# SF32LB52x register map
File version: 1.0
CPU: CM33 r0p1, little endian, MPU, FPU, 3 interrupt priority bits
Registers are 32-bit, read-write, reset 0x0 unless marked. A register's access mark holds for its fields unless they carry their own. Offsets are from the block's base; [hi:lo] are bit positions; {n}, {i} and the like mark numbered series.

## SPI1 — SPI
Base 0x50095000
Same registers: SPI2 0x50096000
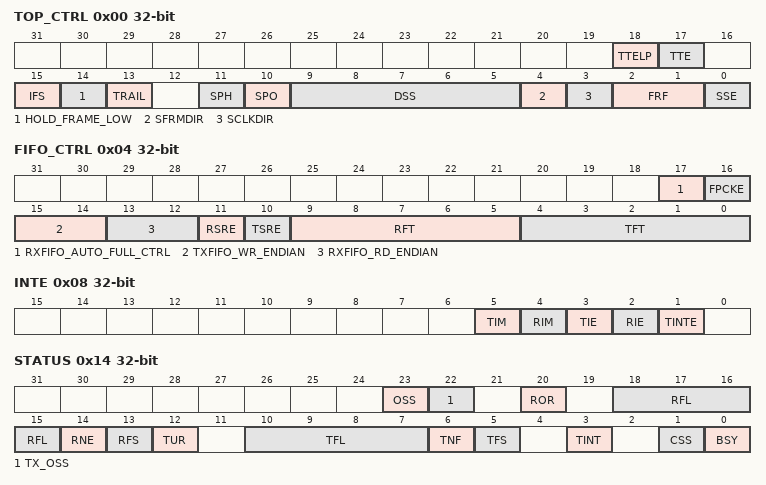
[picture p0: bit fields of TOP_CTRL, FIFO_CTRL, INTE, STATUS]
0x00 TOP_CTRL — Top Control Register
  [18] TTELP — SPI_DO Three-state Enable On Last Phase (can be set only when TI-SSP) 0: SPI_DO is three-stated 1/2 clock cycle after the beginning of the LSB 1: SPI_DO output signal is three-stated on the clock edge that ends the LSB
  [17] TTE — SPI_DO Three-State Enable 0: SPI_DO output signal is not three-stated 1: SPI_DO is three-stated when not transmitting data
  [15] IFS — Invert Frame Signal 0: SPI_CS polarity is as defined in protocol 1: SPI_CS will be inverted from normal-SPI_CS
  [14] HOLD_FRAME_LOW — Hold Frame Low Control 0:After this field is set to 1 and the SPI controller is operating in master mode,the output frame signal SPI_CS will be determined by control FSM. 1:After this field is set to 1 and the SPI controller is operating in master mode, the output frame signal SPI_CS will hold low.
  [13] TRAIL — Trailing Byte 0: Trailing bytes are handled by CPU 1: Trailing bytes are handled by DMA bursts
  [11] SPH — Motorola SPI SPI_CLK phase setting 0: SPI_CLK is inactive until one cycle after the start of a frame and active until 1/2 cycle before the end of a frame 1: SPI_CLK is inactive until 1/2 cycle after the start of a frame and active until one cycle before the end of a frame
  [10] SPO — Motorola SPI SPI_CLK Polarity Setting 0: The inactive or idle state of SPI_CLK is low 1: The inactive or idle state of SPI_CLK is high
  [9:5] DSS — SPI controller Work data size, register bits value 0~31 indicated data size 1~32 bits, usually use data size 8bits, 16bits, 24bits, 32bits
  [4] SFRMDIR — SPI_CS Direction 0: Master mode, SPI controller drives SPI_CS 1: Slave mode, SPI controller receives SPI_CS
  [3] SCLKDIR — SPI_CLK Direction 0: Master mode, SPI controller drives SPI_CLK 1: Slave mode, SPI controller receives SPI_CLK
  [2:1] FRF — Frame Format 0x0: Motorola* Serial Peripheral Interface (SPI) 0x1: Texas Instruments* Synchronous Serial Protocol (SSP) 0x2: National Semiconductor Microwire* 0x3: RSVD
  [0] SSE — SPI controller Enable 0: SPI controller is disabled 1: SPI controller is enabled
0x04 FIFO_CTRL — FIFO Control Register
  [17] RXFIFO_AUTO_FULL_CTRL — Rx FIFO Auto Full Control: After this field is set to 1 and the SPI controller is operating in master mode, the controller FSM returns to IDLE state and stops the SPI_CLK. When Rx FIFO is full, the controller FSM continues transferring data after the RxFIFO is not full. This field is used to avoid an RxFIFO overrun issue. 1: Enable Rx FIFO auto full control
  [16] FPCKE — FIFO Packing Enable 0: FIFO packing mode disabled 1: FIFO packing mode enabled
  [15:14] TXFIFO_WR_ENDIAN — apb_pwdata Write to TxFIFO Endian 0x0: txfifo_wdata[31:0] = apb_pwdata[31:0] 0x1: fifo_wdata[31:0] = {apb_pwdata[15:0], apb_pwdata[31:16]} 0x2: txfifo_wdata[31:0] = {apb_pwdata[7:0], apb_pwdata[15:8], apb_pwdata[23:16], apb_pwdata[31:24]} 0x3: txfifo_wdata[31:0] = {apb_pwdata[23:16], apb_pwdata[31:24], apb_pwdata[7:0], apb_pwdata[15:8]}
  [13:12] RXFIFO_RD_ENDIAN — apb_prdata Read from Rx FIFO Endian 0x0 = apb_prdata[31:0] = rxfifo_wdata[31:0] 0x1 = apb_prdata[31:0] = {rxfifo_wdata[15:0], rxfifo_wdata[31:16]} 0x2 = apb_prdata[31:0]= {rxfifo_wdata[7:0], rxfifo_wdata[15:8], rxfifo_wdata[23:16], rxfifo_wdata[31:24]} 0x3 = apb_prdata[31:0]= {rxfifo_wdata[23:16], rxfifo_wdata[31:24], rxfifo_wdata[7:0], rxfifo_wdata[15:8]}
  [11] RSRE — Receive Service Request Enable 0: RxFIFO DMA service request is disabled 1: RxFIFO DMA service request is enabled
  [10] TSRE — Transmit Service Request Enable 0: TxFIFO DMA service request is disabled 1: TxFIFO DMA service request is enabled
  [9:5] RFT — RXFIFO Trigger Threshold This field sets the threshold level at which RXFIFO asserts interrupt. The level should be set to the preferred threshold value minus 1.
  [4:0] TFT — TXFIFO Trigger Threshold This field sets the threshold level at which TXFIFO asserts interrupt. The level should be set to the preferred threshold value minus 1.
0x08 INTE — Interrupt Enable Register
  [5] TIM — Transmit FIFO Underrun Interrupt Mask 0 : TUR events generate an SPI interrupt 1 : TUR events do NOT generate an SPI interrupt
  [4] RIM — Receive FIFO Overrun Interrupt Mask 0: ROR events generate an SPI interrupt 1: ROR events do NOT generate an SPI interrupt
  [3] TIE — Transmit FIFO Interrupt Enable 0: TxFIFO threshold-level-reached interrupt is disabled 1: TxFIFO threshold-level-reached interrupt is enabled
  [2] RIE — Receive FIFO Interrupt Enable 0: RxFIFO threshold-level-reached interrupt is disabled 1: RxFIFO threshold-level-reached interrupt is enabled
  [1] TINTE — Receiver Time-out Interrupt Enable 0: Receiver time-out interrupt is disabled 1: Receiver time-out interrupt is enabled
0x0C TO — SPI Time Out Register
  [23:0] TIMEOUT — Timeout Value TIMEOUT value is the value (0 to 2^24-1) that defines the time-out interval. The time-out interval is given by the equation shown in the TIMEOUT Interval Equation.
0x10 DATA — SPI DATA Register
  [31:0] DATA — DATA This field is used for data to be written to the TXFIFO read from the RXFIFO.
0x14 STATUS
  [23] OSS — Odd Sample Status 0: RxFIFO entry has two samples 1: RxFIFO entry has one sample Note that this bit needs to be looked at only when FIFO Packing is enabled (FPCKE field in FIFO Control Register is set). Otherwise, this bit is zero. When SPI controller is in Packed mode and the CPU is used instead of DMA to read the RxFIFO, the CPU should make sure that [Receive FIFO Not Empty] = 1 AND this field = 0 before it attempts to read the RxFIFO.
  [22] TX_OSS — TX FIFO Odd Sample Status When SPI controller is in packed mode, the number of samples in the TX FIFO is: ([Transmit FIFO Level]*2 + this field), when [Transmit FIFO Not Full] = 1 32, when [Transmit FIFO Not Full] = 0. The TX FIFO cannot accept new data when [Transmit FIFO Not Full] = 1 and [Transmit FIFO Level] = 15 and this field = 1. (The TX FIFO has 31 samples). 0: TxFIFO entry has an even number of samples 1: TxFIFO entry has an odd number of samples Note that this bit needs to be read only when FIFO Packing is enabled ([FIFO Packing Enable] in the FIFO Control Register is set). Otherwise, this bit is zero.
  [20] ROR — Receive FIFO Overrun 0: RXFIFO has not experienced an overrun 1: Attempted data write to full RXFIFO, causes an interrupt request
  [18:15] RFL — Receive FIFO Level This field is the number of entries minus one in RXFIFO. When the value 0xF is read, the RXFIFO is either empty or full, and software should read the [Receive FIFO Not Empty] field.
  [14] RNE — Receive FIFO Not Empty 0: RXFIFO is empty 1: RXFIFO is not empty
  [13] RFS — Receive FIFO Service Request 0: RXFIFO level is at or below RFT threshold (RFT) or SPI controller is disabled 1: RXFIFO level exceeds RFT threshold (RFT), causes an interrupt request
  [12] TUR — Transmit FIFO Underrun 0: The TXFIFO has not experienced an underrun 1: A read from the TXFIFO was attempted when the TXFIFO was empty, causes an interrupt if it is enabled ([Transmit FIFO Underrun Interrupt Mask] in the INT EN Register is 0)
  [10:7] TFL — Transmit FIFO Level This field is the number of entries in TXFIFO.When the value 0x0 is read, the TXFIFO is either empty or full, and software should read the [Transmit FIFO Not Full] field.
  [6] TNF — Transmit FIFO Not Full 0: TXFIFO is full 1: TXFIFO is not full
  [5] TFS — Transmit FIFO Service Request 0: TX FIFO level exceeds the TFT threshold (TFT + 1) or SPI controller is disabled 1: TXFIFO level is at or below TFT threshold (TFT + 1), causes an interrupt request
  [3] TINT — Receiver Time-out Interrupt 0: No receiver time-out is pending 1: Receiver time-out pending, causes an interrupt request
  [1] CSS — Clock Synchronization Status 0: SPI controller is ready for slave clock operations 1: SPI controller is currently busy synchronizing slave mode signals
  [0] BSY — SPI controller Busy 0: SPI controller is idle or disabled 1: SPI controller is currently transmitting or receiving framed data
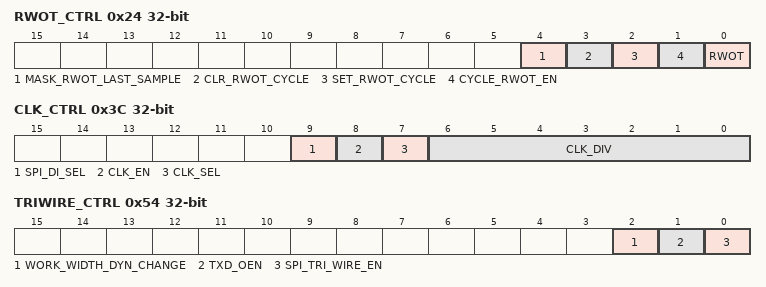
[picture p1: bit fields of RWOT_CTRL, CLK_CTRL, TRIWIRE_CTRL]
0x24 RWOT_CTRL — RWOT Control Register
  [4] MASK_RWOT_LAST_SAMPLE — Mask last_sample_flag in RWOT Mode 1: Mask 0: Unmask
  [3] CLR_RWOT_CYCLE — Clear Internal rwot_counter This field clears the rwot_counter to 0. This field is self cleared after SSE = 1. 1: Clear rwot_counter
  [2] SET_RWOT_CYCLE — Set RWOT Cycle This field is used to set the value of the RWOT_CCM register to the internal rwot_counter. This field is self-cleared after SSE = 1. 1: Set rwot_counter
  [1] CYCLE_RWOT_EN — Enable RWOT Cycle Counter Mode 1: Enable
  [0] RWOT — Receive Without Transmit 0: Transmit/receive mode 1: Receive without transmit mode
0x28 RWOT_CCM — RWOT Counter Cycles Match Register
  [31:0] RWOTCCM — It's just total SPI_CLK Cycles. The value of this register defines the total number of SPI_CLK cycles when SPI controller works in master and RWOT mode. When the rwot_counter matches this value, SPI controller returns to IDLE state and does not output SPI_CLK anymore.
0x2C RWOT_CVWRN — RWOT Counter Value Write for Red Request Register
  [31:0] RWOTCVWR — RWOTCVWR This register prevents the risk of instability on rwot_counter value reading, it's only valid after SPI controller has been enabled Write 0 = No effect Write 1 = Capture value of rwot_counter Read: Returns the captured value of rwot_counter
0x3C CLK_CTRL — CLK Control Register
  [9] SPI_DI_SEL — Select spi_di source. 0: from port SPI_DI. 1: from port SPI_DIO.
  [8] CLK_EN — enable clk for internal logic
  [7] CLK_SEL — 0: select clk_div as clk for SPI controller 1: select clk_sys as clk for SPI controller
  [6:0] CLK_DIV — div ratio from clk_sys
0x54 TRIWIRE_CTRL — Three Wire Mode Control Register
  [2] WORK_WIDTH_DYN_CHANGE — WORK_WIDTH_DYN_CHNAGE 1: SW can dynamicly change TOP_CTRL[9:5] without disabling TOP_CTRL[0] and re-enabling TOP_CTRL[0]
  [1] TXD_OEN — TXD_OEN control when TRI-WIRE mode 1: SPI_DIO is input 0: SPI_DIO is output
  [0] SPI_TRI_WIRE_EN — SPI_THREE_WIRE_MODE_EN 0: normal mode 1: enable TRI-WIRE mode
